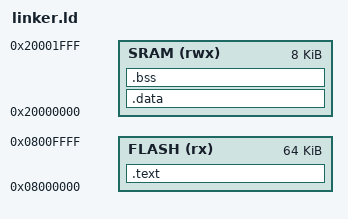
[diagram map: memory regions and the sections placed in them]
ENTRY(Reset_Handler)

MEMORY
{
    FLASH (rx)  : ORIGIN = 0x08000000, LENGTH = 64K
    SRAM  (rwx) : ORIGIN = 0x20000000, LENGTH = 8K
}

SECTIONS
{
    .text :
    {
        KEEP(*(.isr_vector))
        *(.text*)
        *(.rodata*)
    } > FLASH

    _etext = .;
    _sidata = _etext;

    .data : AT(_etext)
    {
        _sdata = .;
        *(.data*)
        _edata = .;
    } > SRAM

    .bss :
    {
        _sbss = .;
        *(.bss*)
        *(COMMON)
        _ebss = .;
    } > SRAM

    _estack = ORIGIN(SRAM) + LENGTH(SRAM);
}
